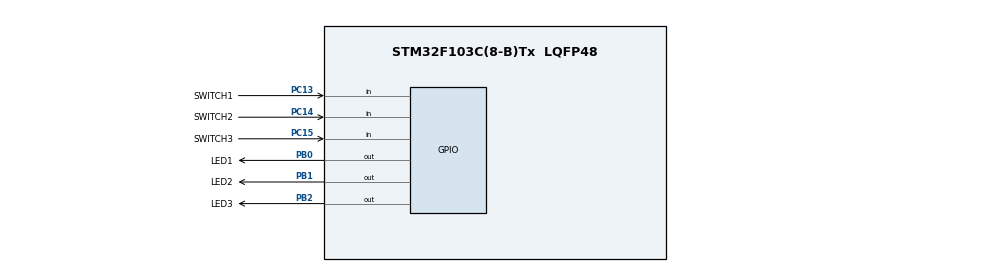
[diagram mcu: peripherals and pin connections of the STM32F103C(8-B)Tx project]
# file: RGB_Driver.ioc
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Mcu.Family=STM32F1
Mcu.Name=STM32F103C(8-B)Tx
Mcu.Package=LQFP48
NVIC.PriorityGroup=NVIC_PRIORITYGROUP_4
PB0.GPIO_Label=LED1
PB0.GPIO_PuPd=GPIO_PULLUP
PB0.GPIO_Speed=GPIO_SPEED_FREQ_HIGH
PB0.PinState=GPIO_PIN_SET
PB0.Signal=GPIO_Output
PB1.GPIO_Label=LED2
PB1.GPIO_PuPd=GPIO_PULLUP
PB1.GPIO_Speed=GPIO_SPEED_FREQ_HIGH
PB1.PinState=GPIO_PIN_SET
PB1.Signal=GPIO_Output
PB2.GPIO_Label=LED3
PB2.GPIO_PuPd=GPIO_PULLUP
PB2.GPIO_Speed=GPIO_SPEED_FREQ_HIGH
PB2.PinState=GPIO_PIN_SET
PB2.Signal=GPIO_Output
PC13-TAMPER-RTC.GPIO_Label=SWITCH1
PC13-TAMPER-RTC.GPIO_PuPd=GPIO_PULLUP
PC13-TAMPER-RTC.Signal=GPIO_Input
PC14-OSC32_IN.GPIO_Label=SWITCH2
PC14-OSC32_IN.GPIO_PuPd=GPIO_PULLUP
PC14-OSC32_IN.Signal=GPIO_Input
PC15-OSC32_OUT.GPIO_Label=SWITCH3
PC15-OSC32_OUT.GPIO_PuPd=GPIO_PULLUP
PC15-OSC32_OUT.Signal=GPIO_Input
ProjectManager.HeapSize=0x200
ProjectManager.StackSize=0x400
ProjectManager.TargetToolchain=STM32CubeIDE
RCC.APB1Freq_Value=8000000
RCC.APB2Freq_Value=8000000
board=custom

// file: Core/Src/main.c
/* USER CODE BEGIN Header */
/**
  ******************************************************************************
  * @file           : main.c
  * @brief          : Main program body
  ******************************************************************************
  * @attention
  *
  * Copyright (c) 2025 STMicroelectronics.
  * All rights reserved.
  *
  * This software is licensed under terms that can be found in the LICENSE file
  * in the root directory of this software component.
  * If no LICENSE file comes with this software, it is provided AS-IS.
  *
  ******************************************************************************
  */
/* USER CODE END Header */
#include "main.h"

void SystemClock_Config(void);
static void MX_GPIO_Init(void);

int main(void)
{

  /* MCU Configuration--------------------------------------------------------*/

  /* Reset of all peripherals, Initializes the Flash interface and the Systick. */
  HAL_Init();

  /* Configure the system clock */
  SystemClock_Config();

  /* Initialize all configured peripherals */
  MX_GPIO_Init();

  /* Infinite loop */
  while (1)
  {

    /* USER CODE BEGIN 3 */
	  if(HAL_GPIO_ReadPin(SWITCH1_GPIO_Port, SWITCH1_Pin)==0){
		  HAL_GPIO_WritePin(LED1_GPIO_Port,LED1_Pin, GPIO_PIN_RESET);
	  }
	  else{
		  HAL_GPIO_WritePin(LED1_GPIO_Port,LED1_Pin, GPIO_PIN_SET);
	  }
	  /*----------------------------------------------------------*/
	  if(HAL_GPIO_ReadPin(SWITCH2_GPIO_Port, SWITCH2_Pin)==0){
	 	  HAL_GPIO_WritePin(LED2_GPIO_Port,LED2_Pin, GPIO_PIN_RESET);
	 	  }
	 	  else{
	      HAL_GPIO_WritePin(LED2_GPIO_Port,LED2_Pin, GPIO_PIN_SET);
	  }
	  /*----------------------------------------------------------*/
	  if(HAL_GPIO_ReadPin(SWITCH3_GPIO_Port, SWITCH3_Pin)==0){
	 	  HAL_GPIO_WritePin(LED3_GPIO_Port,LED3_Pin, GPIO_PIN_RESET);
	 	 	  }
	  else{
	 	  HAL_GPIO_WritePin(LED3_GPIO_Port,LED3_Pin, GPIO_PIN_SET);
	 }
  }
  /* USER CODE END 3 */
}

void SystemClock_Config(void)
{
  RCC_OscInitTypeDef RCC_OscInitStruct = {0};
  RCC_ClkInitTypeDef RCC_ClkInitStruct = {0};

  /** Initializes the RCC Oscillators according to the specified parameters
  * in the RCC_OscInitTypeDef structure.
  */
  RCC_OscInitStruct.OscillatorType = RCC_OSCILLATORTYPE_HSI;
  RCC_OscInitStruct.HSIState = RCC_HSI_ON;
  RCC_OscInitStruct.HSICalibrationValue = RCC_HSICALIBRATION_DEFAULT;
  RCC_OscInitStruct.PLL.PLLState = RCC_PLL_NONE;
  if (HAL_RCC_OscConfig(&RCC_OscInitStruct) != HAL_OK)
  {
    Error_Handler();
  }

  /** Initializes the CPU, AHB and APB buses clocks
  */
  RCC_ClkInitStruct.ClockType = RCC_CLOCKTYPE_HCLK|RCC_CLOCKTYPE_SYSCLK
                              |RCC_CLOCKTYPE_PCLK1|RCC_CLOCKTYPE_PCLK2;
  RCC_ClkInitStruct.SYSCLKSource = RCC_SYSCLKSOURCE_HSI;
  RCC_ClkInitStruct.AHBCLKDivider = RCC_SYSCLK_DIV1;
  RCC_ClkInitStruct.APB1CLKDivider = RCC_HCLK_DIV1;
  RCC_ClkInitStruct.APB2CLKDivider = RCC_HCLK_DIV1;

  if (HAL_RCC_ClockConfig(&RCC_ClkInitStruct, FLASH_LATENCY_0) != HAL_OK)
  {
    Error_Handler();
  }
}

static void MX_GPIO_Init(void)
{
  GPIO_InitTypeDef GPIO_InitStruct = {0};

  /* GPIO Ports Clock Enable */
  __HAL_RCC_GPIOC_CLK_ENABLE();
  __HAL_RCC_GPIOB_CLK_ENABLE();

  /*Configure GPIO pin Output Level */
  HAL_GPIO_WritePin(GPIOB, LED1_Pin|LED2_Pin|LED3_Pin, GPIO_PIN_SET);

  /*Configure GPIO pins : SWITCH1_Pin SWITCH2_Pin SWITCH3_Pin */
  GPIO_InitStruct.Pin = SWITCH1_Pin|SWITCH2_Pin|SWITCH3_Pin;
  GPIO_InitStruct.Mode = GPIO_MODE_INPUT;
  GPIO_InitStruct.Pull = GPIO_PULLUP;
  HAL_GPIO_Init(GPIOC, &GPIO_InitStruct);

  /*Configure GPIO pins : LED1_Pin LED2_Pin LED3_Pin */
  GPIO_InitStruct.Pin = LED1_Pin|LED2_Pin|LED3_Pin;
  GPIO_InitStruct.Mode = GPIO_MODE_OUTPUT_PP;
  GPIO_InitStruct.Pull = GPIO_PULLUP;
  GPIO_InitStruct.Speed = GPIO_SPEED_FREQ_HIGH;
  HAL_GPIO_Init(GPIOB, &GPIO_InitStruct);

}

void Error_Handler(void)
{
  __disable_irq();
  while (1)
  {
  }
}
